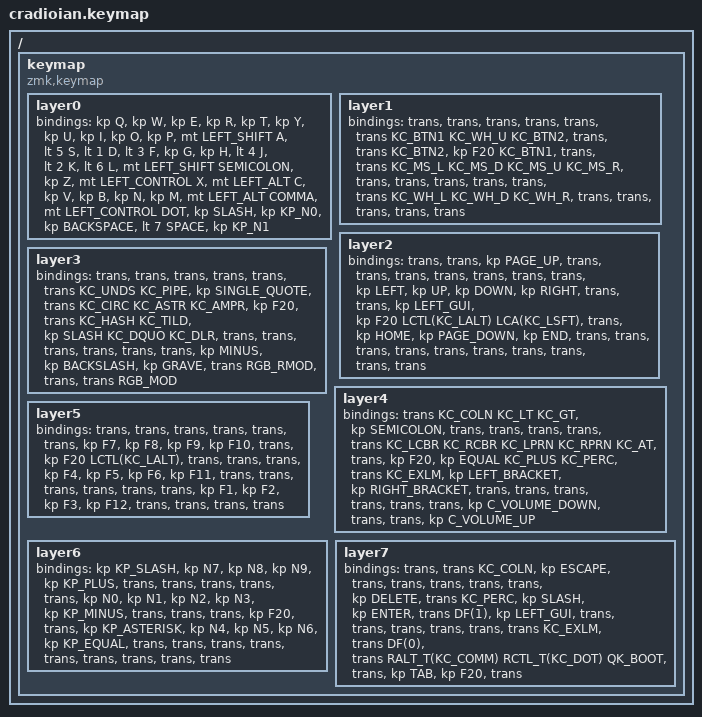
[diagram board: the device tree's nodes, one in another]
 /*
  * Copyright (c) 2020 The ZMK Contributors
  *
  * SPDX-License-Identifier: MIT
  */

  #include <behaviors.dtsi>
  #include <dt-bindings/zmk/keys.h>
  #include <dt-bindings/zmk/bt.h>
  #include <dt-bindings/zmk/ext_power.h>

  / {
    keymap {
      compatible = "zmk,keymap";
  layer0 {
          bindings = <
          &kp Q &kp W &kp E &kp R &kp T &kp Y &kp U &kp I &kp O &kp P &mt LEFT_SHIFT A &lt 5 S &lt 1 D &lt 3 F &kp G &kp H &lt 4 J &lt 2 K &lt 6 L &mt LEFT_SHIFT SEMICOLON &kp Z &mt LEFT_CONTROL X &mt LEFT_ALT C &kp V &kp B &kp N &kp M &mt LEFT_ALT COMMA &mt LEFT_CONTROL DOT &kp SLASH &kp KP_N0 &kp BACKSPACE &lt 7 SPACE &kp KP_N1
          >;
        };layer1 {
          bindings = <
          &trans &trans &trans &trans &trans &trans KC_BTN1 KC_WH_U KC_BTN2 &trans &trans KC_BTN2 &kp F20 KC_BTN1 &trans &trans KC_MS_L KC_MS_D KC_MS_U KC_MS_R &trans &trans &trans &trans &trans &trans KC_WH_L KC_WH_D KC_WH_R &trans &trans &trans &trans &trans
          >;
        };layer2 {
          bindings = <
          &trans &trans &kp PAGE_UP &trans &trans &trans &trans &trans &trans &trans &kp LEFT &kp UP &kp DOWN &kp RIGHT &trans &trans &kp LEFT_GUI &kp F20 LCTL(KC_LALT) LCA(KC_LSFT) &trans &kp HOME &kp PAGE_DOWN &kp END &trans &trans &trans &trans &trans &trans &trans &trans &trans &trans
          >;
        };layer3 {
          bindings = <
          &trans &trans &trans &trans &trans &trans KC_UNDS KC_PIPE &kp SINGLE_QUOTE &trans KC_CIRC KC_ASTR KC_AMPR &kp F20 &trans KC_HASH KC_TILD &kp SLASH KC_DQUO KC_DLR &trans &trans &trans &trans &trans &trans &kp MINUS &kp BACKSLASH &kp GRAVE &trans RGB_RMOD &trans &trans RGB_MOD
          >;
        };layer4 {
          bindings = <
          &trans KC_COLN KC_LT KC_GT &kp SEMICOLON &trans &trans &trans &trans &trans KC_LCBR KC_RCBR KC_LPRN KC_RPRN KC_AT &trans &kp F20 &kp EQUAL KC_PLUS KC_PERC &trans KC_EXLM &kp LEFT_BRACKET &kp RIGHT_BRACKET &trans &trans &trans &trans &trans &trans &kp C_VOLUME_DOWN &trans &trans &kp C_VOLUME_UP
          >;
        };layer5 {
          bindings = <
          &trans &trans &trans &trans &trans &trans &kp F7 &kp F8 &kp F9 &kp F10 &trans &kp F20 LCTL(KC_LALT) &trans &trans &trans &kp F4 &kp F5 &kp F6 &kp F11 &trans &trans &trans &trans &trans &trans &kp F1 &kp F2 &kp F3 &kp F12 &trans &trans &trans &trans
          >;
        };layer6 {
          bindings = <
          &kp KP_SLASH &kp N7 &kp N8 &kp N9 &kp KP_PLUS &trans &trans &trans &trans &trans &kp N0 &kp N1 &kp N2 &kp N3 &kp KP_MINUS &trans &trans &trans &kp F20 &trans &kp KP_ASTERISK &kp N4 &kp N5 &kp N6 &kp KP_EQUAL &trans &trans &trans &trans &trans &trans &trans &trans &trans
          >;
        };layer7 {
          bindings = <
          &trans &trans KC_COLN &kp ESCAPE &trans &trans &trans &trans &trans &kp DELETE &trans KC_PERC &kp SLASH &kp ENTER &trans DF(1) &kp LEFT_GUI &trans &trans &trans &trans &trans &trans KC_EXLM &trans DF(0) &trans RALT_T(KC_COMM) RCTL_T(KC_DOT) QK_BOOT &trans &kp TAB &kp F20 &trans
          >;
        };
    };
  };
  
